# STM32N647xx register map
File version: 1.0
Registers are 32-bit, read-write, reset 0x0 unless marked. A register's access mark holds for its fields unless they carry their own. Offsets are from the block's base; [hi:lo] are bit positions; 'fields as' and 'values as' point back to an identical list.

## ICACHE — Instruction Cache
Base 0x48035000
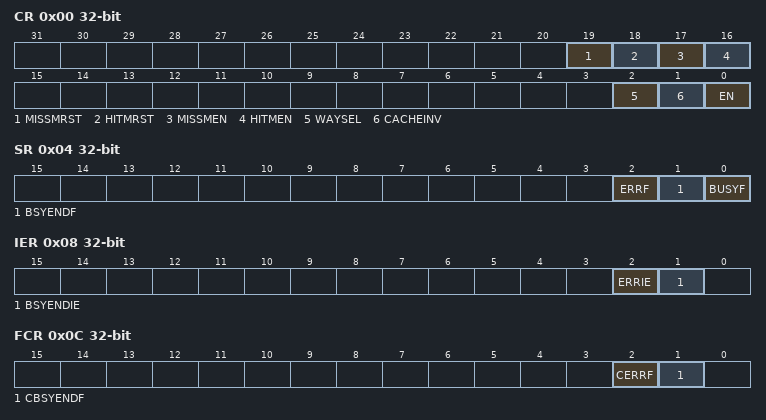
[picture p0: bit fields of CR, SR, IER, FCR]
0x00 CR — ICACHE control register
  [19] MISSMRST — Miss monitor reset
  [18] HITMRST — Hit monitor reset
  [17] MISSMEN — Miss monitor enable
  [16] HITMEN — Hit monitor enable
  [2] WAYSEL — Ways selection
    0=ICACHE_1WAY (1-way cache (direct mapped cache)); 1=ICACHE_4WAYS (4-ways set associative cache (default))
  [1] CACHEINV — Cache invalidation
  [0] EN — Enable
0x04 SR — ICACHE status register
  [2] ERRF — Cache error flag
  [1] BSYENDF — Busy end flag
  [0] BUSYF — Busy flag
0x08 IER — ICACHE interrupt enable register
  [2] ERRIE — Cache error interrupt enable
  [1] BSYENDIE — Busy end interrupt enable
0x0C FCR — ICACHE flag clear register
  [2] CERRF — Cache error flag clear
  [1] CBSYENDF — Busy end flag clear
0x10 HMONR — ICACHE hit monitor register
  [31:0] HITMON — Cache hit monitor register
0x14 MMONR — ICACHE miss monitor register
  [15:0] MISSMON — Cache miss monitor register

## USB1_HS_PHYC
Base 0x4803FC00
Same registers: USB2_HS_PHYC 0x480C0000
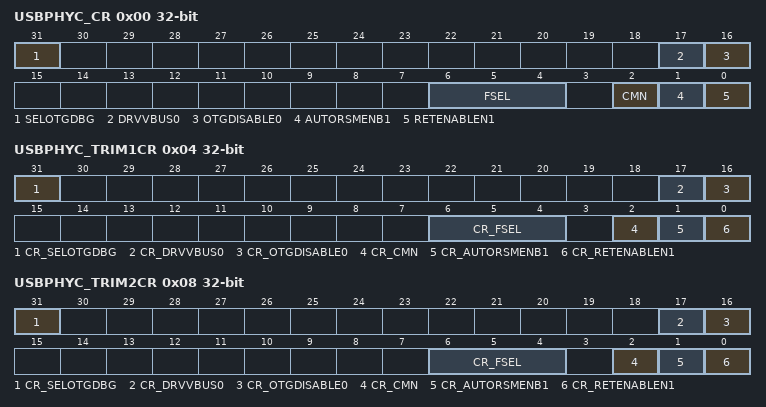
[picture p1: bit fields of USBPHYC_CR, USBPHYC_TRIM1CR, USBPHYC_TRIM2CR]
0x00 USBPHYC_CR — USB HS PHY Control Register
  [31] SELOTGDBG — Select HS PHY debug port
  [17] DRVVBUS0 — Drive VBUS 0
  [16] OTGDISABLE0
  [6:4] FSEL — Frequency selection
  [2] CMN — Controls the power down of analog blocks during Suspend and Sleep
  [1] AUTORSMENB1 — Auto-resume mode enable
  [0] RETENABLEN1 — Retention mode enable
0x04 USBPHYC_TRIM1CR — USB HS PHY Trimming_1 Register
  [31] CR_SELOTGDBG — Select HS PHY debug port
  [17] CR_DRVVBUS0 — Drive VBUS 0
  [16] CR_OTGDISABLE0 — OTG disable 0
  [6:4] CR_FSEL — Frequency selection
  [2] CR_CMN — Controls the power down of analog blocks during Suspend and Sleep
  [1] CR_AUTORSMENB1 — Auto-resume mode enable
  [0] CR_RETENABLEN1 — Retention mode enable
0x08 USBPHYC_TRIM2CR — USB HS PHY Trimming_2 Register
  fields as USBPHYC_TRIM1CR

## CACHEAXI — Axi Cache
Base 0x480DFC00
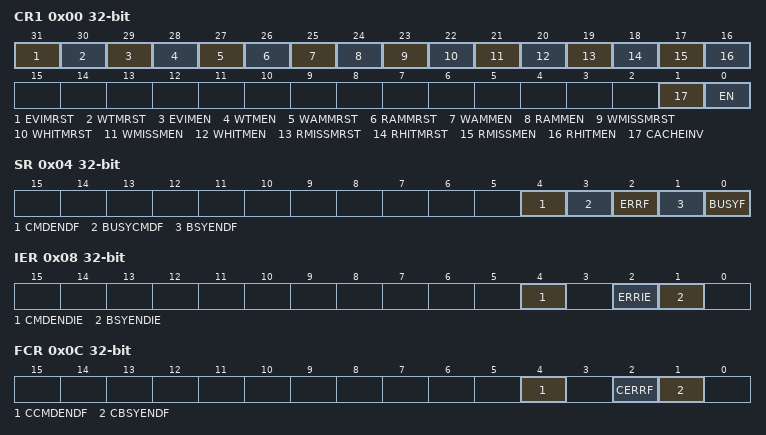
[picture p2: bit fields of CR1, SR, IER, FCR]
0x00 CR1 — CACHEAXI control register 1
  [31] EVIMRST — Eviction monitor reset
  [30] WTMRST — Write-through monitor reset
  [29] EVIMEN — Eviction monitor enable
  [28] WTMEN — Write-through monitor enable
  [27] WAMMRST — Write-allocate miss monitor reset
  [26] RAMMRST — Read-allocate miss monitor reset
  [25] WAMMEN — Write-allocate miss monitor enable
  [24] RAMMEN — Read-allocate miss monitor enable
  [23] WMISSMRST — Write Miss monitor reset
  [22] WHITMRST — Write Hit monitor reset
  [21] WMISSMEN — Write Miss monitor enable
  [20] WHITMEN — Write Hit monitor enable
  [19] RMISSMRST — Read Miss monitor reset
  [18] RHITMRST — Read Hit monitor reset
  [17] RMISSMEN — Read Miss monitor enable
  [16] RHITMEN — Read Hit monitor enable
  [1] CACHEINV — Cache invalidation
  [0] EN — Enable
0x04 SR — CACHEAXI status register
  [4] CMDENDF — Command end flag
  [3] BUSYCMDF — Busy command flag
  [2] ERRF — Cache error flag
  [1] BSYENDF — Busy end flag
  [0] BUSYF — Busy flag
0x08 IER — CACHEAXI interrupt enable register
  [4] CMDENDIE — Command end interrupt enable
  [2] ERRIE — Cache error interrupt enable
  [1] BSYENDIE — Busy end interrupt enable
0x0C FCR — CACHEAXI flag clear register
  [4] CCMDENDF — Command end flag clear
  [2] CERRF — Cache error flag clear
  [1] CBSYENDF — Busy end flag clear
0x10 RHMONR — CACHEAXI read hit monitor register
  [31:0] RHITMON — Cache read hit monitor register
0x14 RMMONR — CACHEAXI read miss monitor register
  [31:0] RMISSMON — Cache read miss monitor register
0x18 RAMMONR — CACHEAXI read-allocate miss monitor register
  [31:0] RAMMON — Cache read-allocate miss monitor counter
0x1C EVIMONR — CACHEAXI eviction monitor register
  [31:0] EVIMON — Cache eviction monitor counter
0x20 WHMONR — CACHEAXI write-hit monitor register
  [31:0] WHITMON — Cache write hit monitor register
0x24 WMMONR — CACHEAXI write-miss monitor register
  [31:0] WMISSMON — Cache write miss monitor register
0x28 WAMMONR — CACHEAXI write-allocate miss monitor register
  [31:0] WAMMON — Cache write-allocate miss monitor register
0x2C WTMONR — CACHEAXI write-through monitor register
  [31:0] WTMON — Cache write-through monitor register
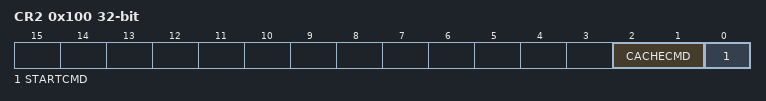
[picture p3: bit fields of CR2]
0x100 CR2 — CACHEAXI control register 2
  [2:1] CACHECMD — Cache command maintenance operation
    1=CLEAN_BY_ADDR; 3=CLEAN_INVALIDATE_BY_ADDR; 0=NO_OPERATION
  [0] STARTCMD — Starts maintenance range command
0x104 CMDRSADDRR — CACHEAXI command start address register
  [31:6] CMDSTARTADDR — Command start address
0x108 CMDREADDRR — CACHEAXI command end address register
  [31:6] CMDENDADDR — Command end address
